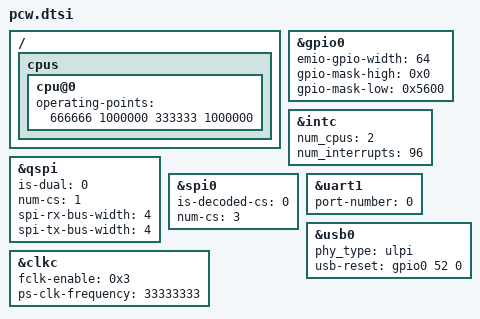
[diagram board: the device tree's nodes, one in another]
/*
 * CAUTION: This file is automatically generated by Xilinx.
 * Version:  
 * Today is: Fri May  8 20:34:54 2020
 */


/ {
	cpus {
		cpu@0 {
			operating-points = <666666 1000000 333333 1000000>;
		};
	};
};
&gpio0 {
	emio-gpio-width = <64>;
	gpio-mask-high = <0x0>;
	gpio-mask-low = <0x5600>;
};
&intc {
	num_cpus = <2>;
	num_interrupts = <96>;
};
&qspi {
	is-dual = <0>;
	num-cs = <1>;
	spi-rx-bus-width = <4>;
	spi-tx-bus-width = <4>;
	status = "okay";
};
&spi0 {
	is-decoded-cs = <0>;
	num-cs = <3>;
	status = "okay";
};
&uart1 {
	device_type = "serial";
	port-number = <0>;
	status = "okay";
};
&usb0 {
	phy_type = "ulpi";
	status = "okay";
	usb-reset = <&gpio0 52 0>;
};
&clkc {
	fclk-enable = <0x3>;
	ps-clk-frequency = <33333333>;
};
